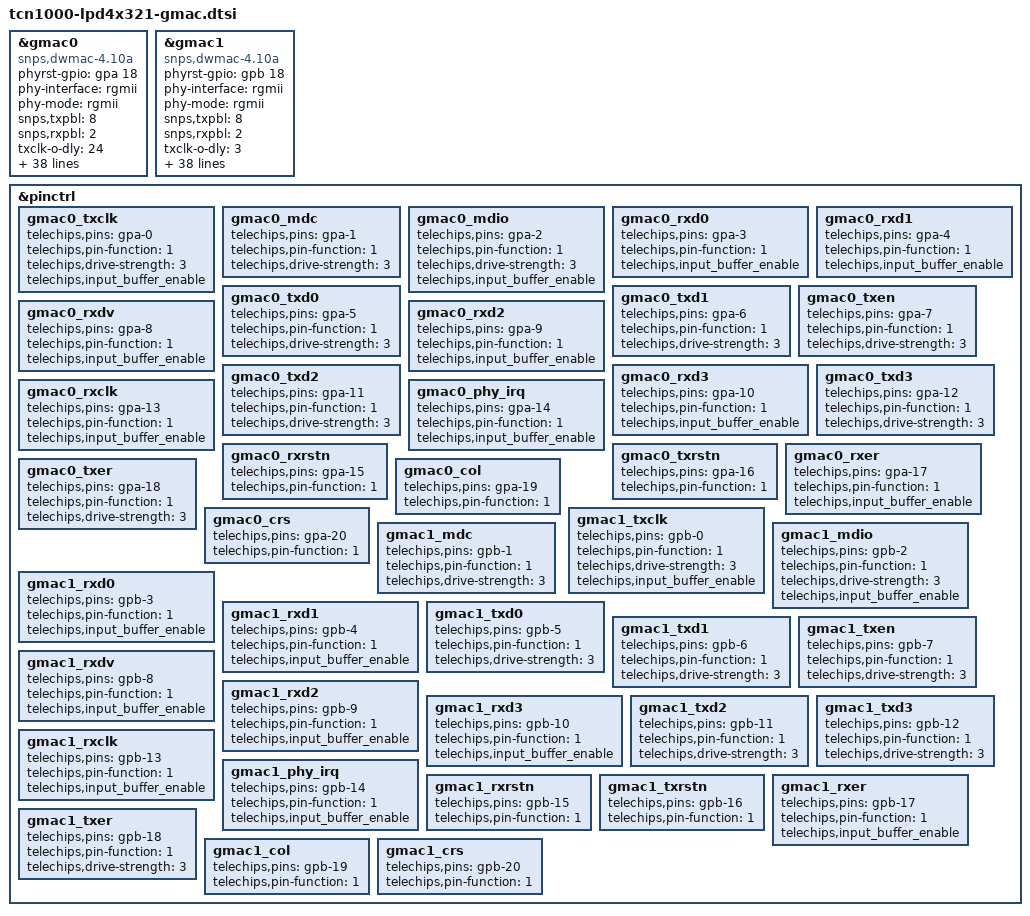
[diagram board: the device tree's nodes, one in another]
// SPDX-License-Identifier: (GPL-2.0-or-later OR MIT)
/*
 * Copyright (C) 2023 Telechips Inc.
 */

&gmac0 {
	status = "okay";
	compatible = "snps,dwmac-4.10a","telechips,gmac";
	phyrst-gpio = <&gpa 18 0>;
	phy-interface = "rgmii";
	interrupt-names = "macirq";
	phy-mode = "rgmii";
	snps,txpbl = <8>;
	snps,rxpbl = <2>;
	txclk-o-dly = <24>;
	txclk-o-inv = <0>;
	txclk-i-dly = <0>;
	txclk-i-inv = <0>;
	txen-dly = <0>;
	txer-dly = <0>;
	txd0-dly = <0>;
	txd1-dly = <0>;
	txd2-dly = <0>;
	txd3-dly = <0>;
	txd4-dly = <0>;
	txd5-dly = <0>;
	txd6-dly = <0>;
	txd7-dly = <0>;
	rxclk-i-dly = <31>;
	rxclk-i-inv = <0>;
	rxdv-dly = <0>;
	rxer-dly = <0>;
	rxd0-dly = <0>;
	rxd1-dly = <0>;
	rxd2-dly = <0>;
	rxd3-dly = <0>;
	rxd4-dly = <0>;
	rxd5-dly = <0>;
	rxd6-dly = <0>;
	rxd7-dly = <0>;
	crs-dly = <0>;
	col-dly = <0>;
	pinctrl-names = "default", "rmii", "rgmii", "sleep";
	pinctrl-0 = <>;
	pinctrl-1 = <&gmac0_mdc &gmac0_mdio
		&gmac0_txclk &gmac0_txen &gmac0_txd0 &gmac0_txd1
		&gmac0_rxer &gmac0_rxdv &gmac0_rxd0 &gmac0_rxd1>;
	pinctrl-2 = <&gmac0_mdc &gmac0_mdio
		&gmac0_txclk &gmac0_txen &gmac0_txd0 &gmac0_txd1 &gmac0_txd2 &gmac0_txd3
		&gmac0_rxclk &gmac0_rxdv &gmac0_rxd0 &gmac0_rxd1 &gmac0_rxd2 &gmac0_rxd3>;
	pinctrl-3 = <>;

#if 0 /* If using fixed link, enable this */
	fixed-link {
		speed = <1000>;
		full-duplex;
	};
#endif
};

&gmac1 {
	status = "okay";
	compatible = "snps,dwmac-4.10a","telechips,gmac";
	phyrst-gpio = <&gpb 18 0>;
	phy-interface = "rgmii";
	interrupt-names = "macirq";
	phy-mode = "rgmii";
	snps,txpbl = <8>;
	snps,rxpbl = <2>;
	txclk-o-dly = <3>;
	txclk-o-inv = <0>;
	txclk-i-dly = <0>;
	txclk-i-inv = <0>;
	txen-dly = <0>;
	txer-dly = <0>;
	txd0-dly = <0>;
	txd1-dly = <0>;
	txd2-dly = <0>;
	txd3-dly = <0>;
	txd4-dly = <0>;
	txd5-dly = <0>;
	txd6-dly = <0>;
	txd7-dly = <0>;
	rxclk-i-dly = <3>;
	rxclk-i-inv = <0>;
	rxdv-dly = <0>;
	rxer-dly = <0>;
	rxd0-dly = <0>;
	rxd1-dly = <0>;
	rxd2-dly = <0>;
	rxd3-dly = <0>;
	rxd4-dly = <0>;
	rxd5-dly = <0>;
	rxd6-dly = <0>;
	rxd7-dly = <0>;
	crs-dly = <0>;
	col-dly = <0>;
	pinctrl-names = "default", "rmii", "rgmii", "sleep";
	pinctrl-0 = <>;
	pinctrl-1 = <&gmac1_mdc &gmac1_mdio
		&gmac1_txclk &gmac1_txen &gmac1_txd0 &gmac1_txd1
		&gmac1_rxer &gmac1_rxdv &gmac1_rxd0 &gmac1_rxd1>;
	pinctrl-2 = <&gmac1_mdc &gmac1_mdio
		&gmac1_txclk &gmac1_txen &gmac1_txd0 &gmac1_txd1 &gmac1_txd2 &gmac1_txd3
		&gmac1_rxclk &gmac1_rxdv &gmac1_rxd0 &gmac1_rxd1 &gmac1_rxd2 &gmac1_rxd3>;
	pinctrl-3 = <>;

#if 0 /* If using fixed link, enable this */
	fixed-link {
		speed = <1000>;
		full-duplex;
	};
#endif
};

&pinctrl {
	gmac0_txclk: gmac0_txclk {
		telechips,pins = "gpa-0";
		telechips,pin-function = <1>;
		telechips,drive-strength = <3>;
		telechips,input_buffer_enable;
	};

	gmac0_mdc: gmac0_mdc {
		telechips,pins = "gpa-1";
		telechips,pin-function = <1>;
		telechips,drive-strength = <3>;
	};

	gmac0_mdio: gmac0_mdio {
		telechips,pins = "gpa-2";
		telechips,pin-function = <1>;
		telechips,drive-strength = <3>;
		telechips,input_buffer_enable;
	};

	gmac0_rxd0: gmac0_rxd0 {
		telechips,pins = "gpa-3";
		telechips,pin-function = <1>;
		telechips,input_buffer_enable;
	};

	gmac0_rxd1: gmac0_rxd1 {
		telechips,pins = "gpa-4";
		telechips,pin-function = <1>;
		telechips,input_buffer_enable;
	};

	gmac0_txd0: gmac0_txd0 {
		telechips,pins = "gpa-5";
		telechips,pin-function = <1>;
		telechips,drive-strength = <3>;
	};

	gmac0_txd1: gmac0_txd1 {
		telechips,pins = "gpa-6";
		telechips,pin-function = <1>;
		telechips,drive-strength = <3>;
	};

	gmac0_txen: gmac0_txen {
		telechips,pins = "gpa-7";
		telechips,pin-function = <1>;
		telechips,drive-strength = <3>;
	};

	gmac0_rxdv: gmac0_rxdv {
		telechips,pins = "gpa-8";
		telechips,pin-function = <1>;
		telechips,input_buffer_enable;
	};

	gmac0_rxd2: gmac0_rxd2 {
		telechips,pins = "gpa-9";
		telechips,pin-function = <1>;
		telechips,input_buffer_enable;
	};

	gmac0_rxd3: gmac0_rxd3 {
		telechips,pins = "gpa-10";
		telechips,pin-function = <1>;
		telechips,input_buffer_enable;
	};

	gmac0_txd2: gmac0_txd2 {
		telechips,pins = "gpa-11";
		telechips,pin-function = <1>;
		telechips,drive-strength = <3>;
	};

	gmac0_txd3: gmac0_txd3 {
		telechips,pins = "gpa-12";
		telechips,pin-function = <1>;
		telechips,drive-strength = <3>;
	};

	gmac0_rxclk: gmac0_rxclk {
		telechips,pins = "gpa-13";
		telechips,pin-function = <1>;
		telechips,input_buffer_enable;
	};

	gmac0_phy_irq: gmac0_phy_irq {
		telechips,pins = "gpa-14";
		telechips,pin-function = <1>;
		telechips,input_buffer_enable;
	};

	gmac0_rxrstn: gmac0_rxrstn {
		telechips,pins = "gpa-15";
		telechips,pin-function = <1>;
	};

	gmac0_txrstn: gmac0_txrstn {
		telechips,pins = "gpa-16";
		telechips,pin-function = <1>;
	};

	gmac0_rxer: gmac0_rxer {
		telechips,pins = "gpa-17";
		telechips,pin-function = <1>;
		telechips,input_buffer_enable;
	};

	gmac0_txer: gmac0_txer {
		telechips,pins = "gpa-18";
		telechips,pin-function = <1>;
		telechips,drive-strength = <3>;
	};

	gmac0_col: gmac0_col {
		telechips,pins = "gpa-19";
		telechips,pin-function = <1>;
	};

	gmac0_crs: gmac0_crs {
		telechips,pins = "gpa-20";
		telechips,pin-function = <1>;
	};

	gmac1_txclk: gmac1_txclk {
		telechips,pins = "gpb-0";
		telechips,pin-function = <1>;
		telechips,drive-strength = <3>;
		telechips,input_buffer_enable;
	};

	gmac1_mdc: gmac1_mdc {
		telechips,pins = "gpb-1";
		telechips,pin-function = <1>;
		telechips,drive-strength = <3>;
	};

	gmac1_mdio: gmac1_mdio {
		telechips,pins = "gpb-2";
		telechips,pin-function = <1>;
		telechips,drive-strength = <3>;
		telechips,input_buffer_enable;
	};

	gmac1_rxd0: gmac1_rxd0 {
		telechips,pins = "gpb-3";
		telechips,pin-function = <1>;
		telechips,input_buffer_enable;
	};

	gmac1_rxd1: gmac1_rxd1 {
		telechips,pins = "gpb-4";
		telechips,pin-function = <1>;
		telechips,input_buffer_enable;
	};

	gmac1_txd0: gmac1_txd0 {
		telechips,pins = "gpb-5";
		telechips,pin-function = <1>;
		telechips,drive-strength = <3>;
	};

	gmac1_txd1: gmac1_txd1 {
		telechips,pins = "gpb-6";
		telechips,pin-function = <1>;
		telechips,drive-strength = <3>;
	};

	gmac1_txen: gmac1_txen {
		telechips,pins = "gpb-7";
		telechips,pin-function = <1>;
		telechips,drive-strength = <3>;
	};

	gmac1_rxdv: gmac1_rxdv {
		telechips,pins = "gpb-8";
		telechips,pin-function = <1>;
		telechips,input_buffer_enable;
	};

	gmac1_rxd2: gmac1_rxd2 {
		telechips,pins = "gpb-9";
		telechips,pin-function = <1>;
		telechips,input_buffer_enable;
	};

	gmac1_rxd3: gmac1_rxd3 {
		telechips,pins = "gpb-10";
		telechips,pin-function = <1>;
		telechips,input_buffer_enable;
	};

	gmac1_txd2: gmac1_txd2 {
		telechips,pins = "gpb-11";
		telechips,pin-function = <1>;
		telechips,drive-strength = <3>;
	};

	gmac1_txd3: gmac1_txd3 {
		telechips,pins = "gpb-12";
		telechips,pin-function = <1>;
		telechips,drive-strength = <3>;
	};

	gmac1_rxclk: gmac1_rxclk {
		telechips,pins = "gpb-13";
		telechips,pin-function = <1>;
		telechips,input_buffer_enable;
	};

	gmac1_phy_irq: gmac1_phy_irq {
		telechips,pins = "gpb-14";
		telechips,pin-function = <1>;
		telechips,input_buffer_enable;
	};

	gmac1_rxrstn: gmac1_rxrstn {
		telechips,pins = "gpb-15";
		telechips,pin-function = <1>;
	};

	gmac1_txrstn: gmac1_txrstn {
		telechips,pins = "gpb-16";
		telechips,pin-function = <1>;
	};

	gmac1_rxer: gmac1_rxer {
		telechips,pins = "gpb-17";
		telechips,pin-function = <1>;
		telechips,input_buffer_enable;
	};

	gmac1_txer: gmac1_txer {
		telechips,pins = "gpb-18";
		telechips,pin-function = <1>;
		telechips,drive-strength = <3>;
	};

	gmac1_col: gmac1_col {
		telechips,pins = "gpb-19";
		telechips,pin-function = <1>;
	};

	gmac1_crs: gmac1_crs {
		telechips,pins = "gpb-20";
		telechips,pin-function = <1>;
	};
};
